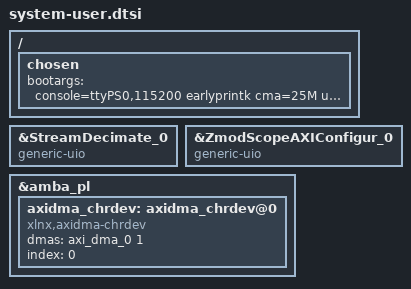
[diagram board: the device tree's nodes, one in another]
/include/ "system-conf.dtsi"
/ {
	chosen {
		bootargs = "console=ttyPS0,115200 earlyprintk cma=25M uio_pdrv_genirq.of_id=generic-uio libuio rw rootwait clk_ignore_unused";
	};

};

&StreamDecimate_0 {
	compatible = "generic-uio";
};

&ZmodScopeAXIConfigur_0 {
	compatible = "generic-uio";
};

&amba_pl {
	axidma_chrdev: axidma_chrdev@0 {
		compatible = "xlnx,axidma-chrdev";
		dmas = <&axi_dma_0 1>;
		dma-names = "rx_channel";
		index = <0>;
	};
};
